# EOS-S3 register map
File version: 0.1
CPU: CM4 r0p1, selectable endian, MPU, FPU, 3 interrupt priority bits
Registers are 32-bit, read-write, reset 0x0 unless marked. A register's access mark holds for its fields unless they carry their own. Offsets are from the block's base; [hi:lo] are bit positions; {n}, {i} and the like mark numbered series.

## WDT — WatchDog Timer
Base 0x40012000
0x00 WDOGLOAD reset 0xFFFFFFFF — The WDOGLOAD Register contains the value from which the counter is to decrement. When this register is written to, the count is immediately restarted from the new value. The minimum valid value for WDOGLOAD is 1.
  [31:0] WDGLOAD — Load value of the WhatchDog timer
0x04 WDOGVALUE reset 0xFFFFFFFF — The WDOGVALUE Register gives the current value of the decrementing counter.
  [31:0] WDGVALUE ro
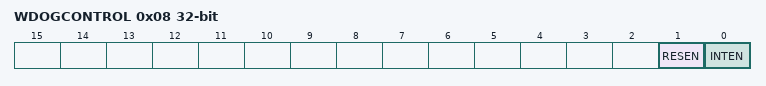
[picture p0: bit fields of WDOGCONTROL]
0x08 WDOGCONTROL — Control register for the WatchDog timer
  [1] RESEN — Enable watchdog reset output, WDOGRES. Acts as a mask for the reset output. Set HIGH to enable the reset or LOW to disable the reset.
  [0] INTEN — Enable the interrupt event, WDOGINT. Set HIGH to enable the counter and the interrupt, or LOW to diable the counter and interrupt. Reloads the counter from the value in WDOGLAND when the interrupt is enabled, after previously being disabled.
0x0C WDOGINTCLR — A write of any value to the WDOGINTCLR Register clears the watchdog interrupt, and reloads the counter from the value in WDOGLOAD.
  [31:0] WDOGINTCLR wo
0x10 WDOGRIS — The WDOGRIS Register indicates the raw interrupt status from the counter. This value is ANDed with the interrupt enable bit from the control register to create the masked interrupt, that is passed to the interrupt output pin.
  [0] WDOGRIS
0x14 WDOGMIS — The WDOGMIS Register indicates the masked interrupt status from the counter. This value is the logical AND of the raw interrupt status with the INTEN bit from the control register, and is the same value that is passed to the interrupt output pin. Enabled interrupt status from the counter.
  [0] WDOGMIS ro
0xC00 WDOGLOCK — The WDOGLOCK Register diables write accesses to all other registers. This is to prevent rogue software from diabling the watchdog functionality. Writing a value 0x1ACCE551 enables write access to all other registers. Writing any other value disables write accesses.
  [31:0] WDOGLOCK
    0=locked (Write access is enabled, not locked); 1=not_locked (Write access is disabled, locked)
0xF00 WDOGITCR — The WDOGITCR Register enables integration Test mode. When in this more, the Test output register directly controls the masted interrup output, WDOGINT, and reset output, WDOGRES. Integration Test mode Enable [0] When set HIGH, places th watchdog into integration Test mode.
  [0] WDOGITCR
0xF04 WDOGITOP — Watchdog Integration Test Output Set Register When the WDOGITOP Register is in integration Test mode, the values in this register directly drive the enabled interrupt output and reset output.
  [1:0] WDOGITOP wo
    0=wdocres (Select integration Test with WDOCRES value); 1=wdogint (Select integration Test with WDOGINT value)
0xFD0 WDOGPERIPHID4 reset 0x4 — Peripheral ID Register 4: [7:4] Block count. [3:0] jep106_c_code.
  [7:0] WDOGPERIPHID4 ro
{0xFC0+4i} WDOGPERIPHID{i} (i=5..7) — Peripheral ID Register {i}.
  [7:0] WDOGPERIPHID{i} ro
0xFE0 WDOGPERIPHID0 reset 0x24 — Periperhal ID Register 0. [7:0] Part number[7:0].
  [7:0] WDOGPERIPHID0 ro
0xFE4 WDOGPERIPHID1 reset 0xB8 — Peripheral ID Register 1. [7:4] jep106_id_3_0. [3:0] Part number [11:8].
  [7:0] WDOGPERIPHID1 ro
0xFE8 WDOGPERIPHID2 reset 0x1B — Peripheral ID Register 2. [7:4] Revision. [3] jedec_used. [2:0] jep106_id_6_4.
  [7:0] WDOGPERIPHID2 ro
0xFEC WDOGPERIPHID3 — Peripherial ID Register 3. [7:4] ECO revision number. [3:0] Customer modification number.
  [7:0] WDOGPERIPHID3 ro
0xFF0 WDOGPCELLID0 reset 0xD — Component ID Register 0.
  [7:0] WDOGPCELLID0 ro
0xFF4 WDOGPCELLID1 reset 0xF0 — Component ID Register 1.
  [7:0] WDOGPCELLID1 ro
0xFF8 WDOGPCELLID2 reset 0x5 — Component ID Register 2.
  [7:0] WDOGPCELLID2 ro
0xFFC WDOGPCELLID3 reset 0xB1 — Component ID Register 3.
  [7:0] WDOGPCELLID3 ro
